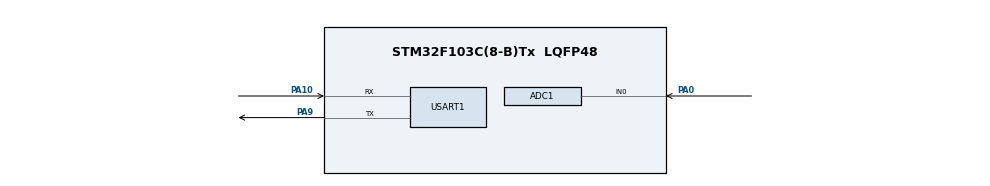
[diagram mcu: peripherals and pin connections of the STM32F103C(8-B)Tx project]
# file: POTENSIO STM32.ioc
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ADC1.Channel-0\#ChannelRegularConversion=ADC_CHANNEL_0
ADC1.NbrOfConversionFlag=1
ADC1.Rank-0\#ChannelRegularConversion=1
ADC1.SamplingTime-0\#ChannelRegularConversion=ADC_SAMPLETIME_1CYCLE_5
ADC1.master=1
Mcu.Family=STM32F1
Mcu.Name=STM32F103C(8-B)Tx
Mcu.Package=LQFP48
NVIC.PriorityGroup=NVIC_PRIORITYGROUP_4
PA0-WKUP.Signal=ADCx_IN0
PA10.Mode=Asynchronous
PA10.Signal=USART1_RX
PA13.Mode=Serial_Wire
PA13.Signal=SYS_JTMS-SWDIO
PA14.Mode=Serial_Wire
PA14.Signal=SYS_JTCK-SWCLK
PA9.Mode=Asynchronous
PA9.Signal=USART1_TX
PD0-OSC_IN.Mode=HSE-External-Oscillator
PD0-OSC_IN.Signal=RCC_OSC_IN
PD1-OSC_OUT.Mode=HSE-External-Oscillator
PD1-OSC_OUT.Signal=RCC_OSC_OUT
ProjectManager.HeapSize=0x200
ProjectManager.StackSize=0x400
ProjectManager.TargetToolchain=MDK-ARM V5.32
RCC.APB1Freq_Value=8000000
RCC.APB2Freq_Value=8000000
SH.ADCx_IN0.0=ADC1_IN0,IN0
USART1.VirtualMode=VM_ASYNC
board=custom

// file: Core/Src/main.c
/* USER CODE BEGIN Header */
/**
  ******************************************************************************
  * @file           : main.c
  * @brief          : Main program body
  ******************************************************************************
  * @attention
  *
  * Copyright (c) 2025 STMicroelectronics.
  * All rights reserved.
  *
  * This software is licensed under terms that can be found in the LICENSE file
  * in the root directory of this software component.
  * If no LICENSE file comes with this software, it is provided AS-IS.
  *
  ******************************************************************************
  */
/* USER CODE END Header */
#include "main.h"
#include "stm32f1xx_hal.h"

/* USER CODE BEGIN PD */
// Motor driver 1
#define PWM_1 GPIO_PIN_5
#define RPWM_1 GPIO_PIN_6
#define LPWM_1 GPIO_PIN_7
#define MOTOR_PORT_1 GPIOA

// Motor driver 2
#define PWM_2 GPIO_PIN_8
#define RPWM_2 GPIO_PIN_9
#define LPWM_2 GPIO_PIN_10
#define MOTOR_PORT_2 GPIOB

// Motor driver 3
#define PWM_3 GPIO_PIN_11
#define RPWM_3 GPIO_PIN_12
#define LPWM_3 GPIO_PIN_13
#define MOTOR_PORT_3 GPIOC
/* USER CODE END PD */

ADC_HandleTypeDef hadc1;
UART_HandleTypeDef huart1;

/* USER CODE BEGIN PV */
int input[6];
/* USER CODE END PV */

void SystemClock_Config(void);
void MX_GPIO_Init(void);
void MX_ADC1_Init(void);
void MX_USART1_UART_Init(void);

/* USER CODE BEGIN 0 */
		int _write(int file, char *ptr, int len) {
				HAL_UART_Transmit(&huart1, (uint8_t*) ptr, len, HAL_MAX_DELAY);
				return len;
		}

		void HAL_GPIO_EXTI_Callback(uint16_t GPIO_Pin) {
				static uint32_t timer[6] = {0};
				for (int i = 0; i < 6; i++) {
						if (GPIO_Pin == (GPIO_PIN_0 << i)) {
								uint32_t now = HAL_GetTick();
								input[i] = now - timer[i];
								timer[i] = now;
						}
				}
		}

		void motor_control(GPIO_TypeDef *MOTOR_PORT, uint16_t RPWM, uint16_t LPWM, int speed) {
				if (speed > 0) {
						HAL_GPIO_WritePin(MOTOR_PORT, RPWM, GPIO_PIN_SET);
						HAL_GPIO_WritePin(MOTOR_PORT, LPWM, GPIO_PIN_RESET);
				} else if (speed < 0) {
						HAL_GPIO_WritePin(MOTOR_PORT, RPWM, GPIO_PIN_RESET);
						HAL_GPIO_WritePin(MOTOR_PORT, LPWM, GPIO_PIN_SET);
				} else {
						HAL_GPIO_WritePin(MOTOR_PORT, RPWM, GPIO_PIN_RESET);
						HAL_GPIO_WritePin(MOTOR_PORT, LPWM, GPIO_PIN_RESET);
				}
		}
/* USER CODE END 0 */

int main(void)
{

  /* MCU Configuration--------------------------------------------------------*/

  /* Reset of all peripherals, Initializes the Flash interface and the Systick. */
  HAL_Init();

  /* Configure the system clock */
  SystemClock_Config();

  /* Initialize all configured peripherals */
  MX_GPIO_Init();
	MX_ADC1_Init();
	MX_USART1_UART_Init();
	uint32_t adc_value;

  /* Infinite loop */
  /* USER CODE BEGIN WHILE */
  while (1)
  {
     HAL_ADC_Start(&hadc1);
     HAL_ADC_PollForConversion(&hadc1, HAL_MAX_DELAY);
     adc_value = HAL_ADC_GetValue(&hadc1);
     printf("ADC Value: %lu\n", adc_value);

     motor_control(MOTOR_PORT_1, RPWM_1, LPWM_1, 1);
     HAL_Delay(1000);
     motor_control(MOTOR_PORT_1, RPWM_1, LPWM_1, -1);
     HAL_Delay(1000);
    /* USER CODE END WHILE */

  }
}
/* GPIO Initialization */
void MX_ADC1_Init(void) {
    ADC_ChannelConfTypeDef sConfig = {0};
    hadc1.Instance = ADC1;
    hadc1.Init.ScanConvMode = ADC_SCAN_ENABLE;
    hadc1.Init.ContinuousConvMode = ENABLE;
    hadc1.Init.DiscontinuousConvMode = DISABLE;
    hadc1.Init.DataAlign = ADC_DATAALIGN_RIGHT;
    hadc1.Init.NbrOfConversion = 1;
    HAL_ADC_Init(&hadc1);

    sConfig.Channel = ADC_CHANNEL_0;
    sConfig.Rank = ADC_REGULAR_RANK_1;
    HAL_ADC_ConfigChannel(&hadc1, &sConfig);
}

void MX_USART1_UART_Init(void) {
    huart1.Instance = USART1;
    huart1.Init.BaudRate = 115200;
    huart1.Init.WordLength = UART_WORDLENGTH_8B;
    huart1.Init.StopBits = UART_STOPBITS_1;
    huart1.Init.Parity = UART_PARITY_NONE;
    huart1.Init.Mode = UART_MODE_TX_RX;
    HAL_UART_Init(&huart1);
}

/* GPIO Initialization */
void MX_GPIO_Init(void) {
    GPIO_InitTypeDef GPIO_InitStruct = {0};
    __HAL_RCC_GPIOA_CLK_ENABLE();
    __HAL_RCC_GPIOB_CLK_ENABLE();
    __HAL_RCC_GPIOC_CLK_ENABLE();
    __HAL_RCC_GPIOD_CLK_ENABLE();

    GPIO_InitStruct.Pin = RPWM_1 | LPWM_1;
    GPIO_InitStruct.Mode = GPIO_MODE_OUTPUT_PP;
    GPIO_InitStruct.Speed = GPIO_SPEED_FREQ_LOW;
    HAL_GPIO_Init(MOTOR_PORT_1, &GPIO_InitStruct);
}

void SystemClock_Config(void)
{
  RCC_OscInitTypeDef RCC_OscInitStruct = {0};
  RCC_ClkInitTypeDef RCC_ClkInitStruct = {0};

  /** Initializes the RCC Oscillators according to the specified parameters
  * in the RCC_OscInitTypeDef structure.
  */
  RCC_OscInitStruct.OscillatorType = RCC_OSCILLATORTYPE_HSI;
  RCC_OscInitStruct.HSIState = RCC_HSI_ON;
  RCC_OscInitStruct.HSICalibrationValue = RCC_HSICALIBRATION_DEFAULT;
  RCC_OscInitStruct.PLL.PLLState = RCC_PLL_NONE;
  if (HAL_RCC_OscConfig(&RCC_OscInitStruct) != HAL_OK)
  {
    Error_Handler();
  }

  /** Initializes the CPU, AHB and APB buses clocks
  */
  RCC_ClkInitStruct.ClockType = RCC_CLOCKTYPE_HCLK|RCC_CLOCKTYPE_SYSCLK
                              |RCC_CLOCKTYPE_PCLK1|RCC_CLOCKTYPE_PCLK2;
  RCC_ClkInitStruct.SYSCLKSource = RCC_SYSCLKSOURCE_HSI;
  RCC_ClkInitStruct.AHBCLKDivider = RCC_SYSCLK_DIV1;
  RCC_ClkInitStruct.APB1CLKDivider = RCC_HCLK_DIV1;
  RCC_ClkInitStruct.APB2CLKDivider = RCC_HCLK_DIV1;

  if (HAL_RCC_ClockConfig(&RCC_ClkInitStruct, FLASH_LATENCY_0) != HAL_OK)
  {
    Error_Handler();
  }
}

void MX_GPIO_Init(void)
{

  /* GPIO Ports Clock Enable */
  __HAL_RCC_GPIOD_CLK_ENABLE();
  __HAL_RCC_GPIOA_CLK_ENABLE();

}

void Error_Handler(void)
{
  __disable_irq();
  while (1)
  {
  }
}
